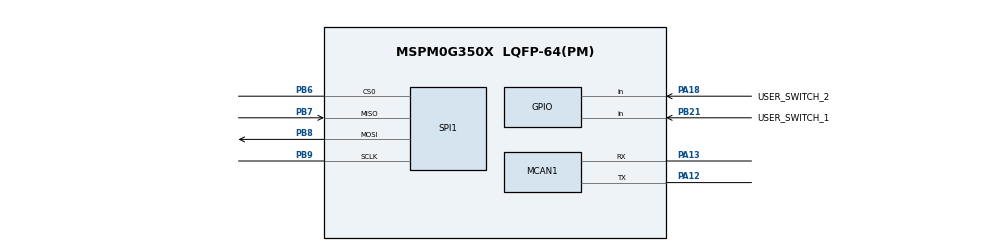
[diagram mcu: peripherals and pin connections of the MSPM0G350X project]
// @cliArgs --device "MSPM0G350X" --package "LQFP-64(PM)" --part "Default"
// @cliArgs --board /ti/boards/LP_MSPM0G3507 --rtos nortos

/**
 * Import the modules used in this configuration.
 */
const GPIO   = scripting.addModule("/ti/driverlib/GPIO", {}, false);
const GPIO1  = GPIO.addInstance();
const GPIO2  = GPIO.addInstance();
const MCAN   = scripting.addModule("/ti/driverlib/MCAN", {}, false);
const MCAN1  = MCAN.addInstance();
const SPI    = scripting.addModule("/ti/driverlib/SPI", {}, false);
const SPI1   = SPI.addInstance();
const SYSCTL = scripting.addModule("/ti/driverlib/SYSCTL");

/**
 * Write custom configuration values to the imported modules.
 */
const mux4       = system.clockTree["EXHFMUX"];
mux4.inputSelect = "EXHFMUX_XTAL";

const pinFunction3     = system.clockTree["HFCLKEXT"];
pinFunction3.inputFreq = 40;

const pinFunction4        = system.clockTree["HFXT"];
pinFunction4.enable       = true;
pinFunction4.HFXTStartup  = 10;
pinFunction4.HFCLKMonitor = true;
pinFunction4.inputFreq    = 40;

GPIO1.$name                              = "GPIO_SWITCHES1";
GPIO1.port                               = "PORTB";
GPIO1.portSegment                        = "Upper";
GPIO1.associatedPins[0].$name            = "USER_SWITCH_1";
GPIO1.associatedPins[0].direction        = "INPUT";
GPIO1.associatedPins[0].internalResistor = "PULL_UP";
GPIO1.associatedPins[0].polarity         = "FALL";
GPIO1.associatedPins[0].interruptEn      = true;
GPIO1.associatedPins[0].pin.$assign      = "PB21";

const Board = scripting.addModule("/ti/driverlib/Board", {}, false);

GPIO2.$name                         = "GPIO_SWITCHES2";
GPIO2.port                          = "PORTA";
GPIO2.portSegment                   = "Upper";
GPIO2.associatedPins[0].$name       = "USER_SWITCH_2";
GPIO2.associatedPins[0].direction   = "INPUT";
GPIO2.associatedPins[0].polarity    = "RISE";
GPIO2.associatedPins[0].interruptEn = true;
GPIO2.associatedPins[0].pin.$assign = "PA18";

MCAN1.$name                    = "MCAN0";
MCAN1.wkupReqEnable            = true;
MCAN1.autoWkupEnable           = true;
MCAN1.emulationEnable          = true;
MCAN1.tdcEnable                = true;
MCAN1.additionalCoreConfig     = true;
MCAN1.rrfe                     = true;
MCAN1.rrfs                     = true;
MCAN1.anfe                     = "1";
MCAN1.anfs                     = "1";
MCAN1.txEventFIFOWaterMark     = 0;
MCAN1.interruptFlags           = ["DL_MCAN_INTERRUPT_ARA","DL_MCAN_INTERRUPT_BEU","DL_MCAN_INTERRUPT_BO","DL_MCAN_INTERRUPT_DRX","DL_MCAN_INTERRUPT_ELO","DL_MCAN_INTERRUPT_EP","DL_MCAN_INTERRUPT_EW","DL_MCAN_INTERRUPT_MRAF","DL_MCAN_INTERRUPT_PEA","DL_MCAN_INTERRUPT_PED","DL_MCAN_INTERRUPT_TC","DL_MCAN_INTERRUPT_TEFN","DL_MCAN_INTERRUPT_TOO","DL_MCAN_INTERRUPT_TSW","DL_MCAN_INTERRUPT_WDI"];
MCAN1.interruptLine            = ["DL_MCAN_INTR_LINE_NUM_1"];
MCAN1.interruptLine1Flag       = ["DL_MCAN_INTR_MASK_ALL"];
MCAN1.m0interrupts             = ["DL_MCAN_MSP_INTERRUPT_LINE1"];
MCAN1.overrideRetention        = true;
MCAN1.stdFiltType              = "01";
MCAN1.flesa                    = 0;
MCAN1.lse                      = 0;
MCAN1.desiredDataRate          = 2;
MCAN1.rxFIFO1waterMark         = 0;
MCAN1.rxFIFO0waterMark         = 0;
MCAN1.lss                      = 0;
MCAN1.rxFIFO0startAddr         = 0;
MCAN1.rxFIFO1startAddr         = 0;
MCAN1.rxBufStartAddr           = 0;
MCAN1.rxFIFO1size              = 0;
MCAN1.rxFIFO0size              = 0;
MCAN1.txFIFOSize               = 10;
MCAN1.txStartAddr              = 12;
MCAN1.txEventFIFOStartAddr     = 640;
MCAN1.enableInterrupt          = true;
MCAN1.peripheral.$assign       = "CANFD0";
MCAN1.peripheral.rxPin.$assign = "PA13";
MCAN1.peripheral.txPin.$assign = "PA12";

SPI1.$name                      = "SPI_0";
SPI1.enableDMAEvent1            = false;
SPI1.enableDMAEvent2            = false;
SPI1.targetBitRate              = 4000000;
SPI1.dataSize                   = 16;
SPI1.peripheral.$assign         = "SPI1";
SPI1.peripheral.sclkPin.$assign = "PB9";
SPI1.peripheral.mosiPin.$assign = "PB8";
SPI1.peripheral.misoPin.$assign = "PB7";
SPI1.peripheral.cs0Pin.$assign  = "PB6";

SYSCTL.CANCLKSource    = "HFCLK";
SYSCTL.useHFCLK_Manual = true;
SYSCTL.HFCLKSource     = "HFXT";
SYSCTL.HFCLK_Freq      = 40000000;
SYSCTL.HFCLKMonitor    = true;
SYSCTL.HFXTStartup     = 10;
SYSCTL.forceDefaultClkConfig = true;
SYSCTL.clockTreeEn      = true;
